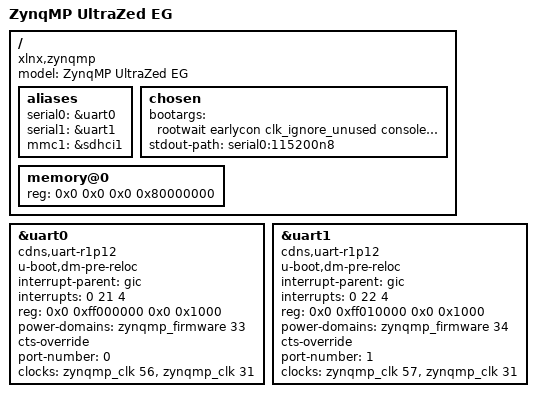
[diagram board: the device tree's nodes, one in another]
// SPDX-License-Identifier: GPL-2.0+
/*
 * dts file for Xilinx ZynqMP ZCU100 revC
 *
 * (C) Copyright 2016 - 2020, Xilinx, Inc.
 *
 * Michal Simek <michal.simek@xilinx.com>
 * Nathalie Chan King Choy
 */

/dts-v1/;

#include "zynqmp.dtsi"
#include "zynqmp-clk-ccf.dtsi"
#include <dt-bindings/input/input.h>
#include <dt-bindings/interrupt-controller/irq.h>
#include <dt-bindings/gpio/gpio.h>
#include <dt-bindings/phy/phy.h>

/ {
	model = "ZynqMP UltraZed EG";
	compatible = "xlnx,zynqmp";

	aliases {
		serial0 = &uart0;
		serial1 = &uart1;
		mmc1 = &sdhci1;
	};

	chosen {
		bootargs = "rootwait earlycon clk_ignore_unused console=ttyPS0,115200 earlyprintk cpuidle.off=1 root=/dev/mmcblk1p2 rw";
		stdout-path = "serial0:115200n8";
	};

	memory@0 {
		device_type = "memory";
		reg = <0x0 0x0 0x0 0x80000000>;
	};
};

	&uart0 {
		u-boot,dm-pre-reloc;
		compatible = "cdns,uart-r1p12", "xlnx,xuartps";
		status = "okay";
		interrupt-parent = <&gic>;
		interrupts = <0 21 4>;
		reg = <0x0 0xff000000 0x0 0x1000>;
		clock-names = "uart_clk", "pclk";
		power-domains = <&zynqmp_firmware 33>;
		cts-override;
		device_type = "serial";
		port-number = <0>;
		clocks = <&zynqmp_clk 56>, <&zynqmp_clk 31>;
  };

  &uart1 {
		u-boot,dm-pre-reloc;
		compatible = "cdns,uart-r1p12", "xlnx,xuartps";
		status = "okay";
		interrupt-parent = <&gic>;
		interrupts = <0 22 4>;
		reg = <0x0 0xff010000 0x0 0x1000>;
		clock-names = "uart_clk", "pclk";
		power-domains = <&zynqmp_firmware 34>;
		cts-override ;
		device_type = "serial";
		port-number = <1>;
		clocks = <&zynqmp_clk 57>, <&zynqmp_clk 31>;
	};
